# BL808 register map
File version: 0.1
Registers are access not given, no defined reset value unless marked. A register's access mark holds for its fields unless they carry their own. Offsets are from the block's base; [hi:lo] are bit positions; {n}, {i} and the like mark numbered series.

## DMA2D
Base 0x30006000
0x00 DMA2D_IntStatus
  [7:0] IntStatus ro — Status of the DMA interrupts after masking
0x04 DMA2D_IntTCStatus
  [7:0] IntTCStatus ro — Interrupt terminal count request status
0x08 DMA2D_IntTCClear
  [7:0] IntTCClear write-once — Terminal count request clear
0x0C DMA2D_EnbldChns
  [7:0] EnabledChannels ro — Channel enable status
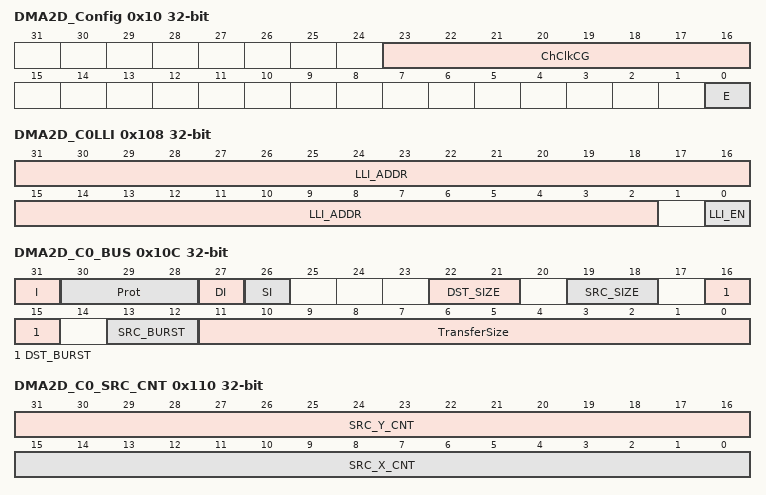
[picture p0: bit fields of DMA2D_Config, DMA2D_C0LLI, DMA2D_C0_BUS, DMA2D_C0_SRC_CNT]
0x10 DMA2D_Config
  [23:16] ChClkCG rw — Channel Clock cg enable
  [0] E rw — SMDMA Enable.
0x14 DMA2D_Sync rw
  [31:0] DMA_Sync — DMA synchronization logic for DMA request signals: 0 = enable, 1 = disable
0x18 DMA2D_SoftBReq rw
  [31:0] SoftBReq — Software burst request
0x1C DMA2D_SoftLBReq rw
  [31:0] SoftLBReq — Software last burst request
0x20 DMA2D_SoftSReq rw
  [31:0] SoftSReq — Software signle request
0x24 DMA2D_SoftLSReq rw
  [31:0] SoftLSReq — Software last signle request
0x100 DMA2D_C0SrcAddr rw
  [31:0] SrcAddr — DMA source address
0x104 DMA2D_C0DstAddr rw
  [31:0] DstAddr — DMA Destination address
0x108 DMA2D_C0LLI
  [31:2] LLI_ADDR rw — Next linked list address
  [0] LLI_EN rw — Next LLI enable
0x10C DMA2D_C0_BUS
  [31] I rw — Terminal count interrupt enable bit. It controls whether the current LLI is expected to trigger the terminal count interrupt.
  [30:28] Prot rw — Hprot Setting
  [27] DI rw — Only work when reg_dma_2d_en = 0 Destination increment. When set, the Destination address is incremented after each transfer.
  [26] SI rw — Only work when reg_dma_2d_en = 0 Source increment. When set, the source address is incremented after each transfer.
  [22:21] DST_SIZE rw — Destination transfer width: 8/16/32
  [19:18] SRC_SIZE rw — Source transfer width: 8/16/32
  [16:15] DST_BURST rw — Destination burst size: 1/4/8/16
  [13:12] SRC_BURST rw
  [11:0] TransferSize rw — Only work when reg_dma_2d_en = 0 Transfer size: 0~4095. Number of data transfers left to complete when the SMDMA is the flow controller.
0x110 DMA2D_C0_SRC_CNT rw
  [31:16] SRC_Y_CNT — Only work when reg_dma_2d_en = 1 Source Y-direction Count
  [15:0] SRC_X_CNT — Only work when reg_dma_2d_en = 1 Source X-direction Count
0x114 DMA2D_C0_SRC_XIC rw
  [31:0] SRC_X_INCR — Only work when reg_dma_2d_en = 1 Source Y-direction address increment Must allign "SWidth" setting [16] sign-bit
0x118 DMA2D_C0_SRC_YIC rw
  [31:0] SRC_Y_INCR — Only work when reg_dma_2d_en = 1 Source Y-direction address increment Must allign "SWidth" setting [16] sign-bit
0x11C DMA2D_C0_DST_CNT
  [15:0] DST_X_CNT rw — Only work when reg_dma_2d_en = 1 Source X-direction Count
0x120 DMA2D_C0_DST_XIC rw
  [31:0] DST_X_INCR — Only work when reg_dma_2d_en = 1 Source Y-direction address increment Must allign "SWidth" setting [16] sign-bit
0x124 DMA2D_C0_DST_YIC rw
  [31:0] DST_Y_INCR — Only work when reg_dma_2d_en = 1 Desitination Y-direction address increment Must allign "DWidth" setting [16] sign-bit
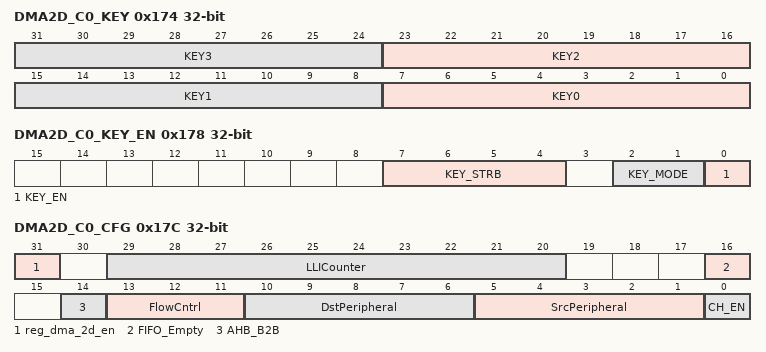
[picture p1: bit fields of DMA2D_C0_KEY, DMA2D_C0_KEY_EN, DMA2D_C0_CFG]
0x174 DMA2D_C0_KEY rw
  [8n+7:8n] KEY{n} (n=0..3) — Key value
0x178 DMA2D_C0_KEY_EN
  [7:4] KEY_STRB rw — According Key mode set Key STRB Key mode : Key STRB 2'd0 : 4'h1 2'd1 : 4'h3 2'd2 : 4'h7 2'd3 : 4'hf
  [2:1] KEY_MODE rw — Key Mode 2'd0 : 8-bit mode 2'd1 : 16-bit mode 2'd2 : 24-bit mode 2'd3 : 32-bit mode
  [0] KEY_EN rw — Key enable
0x17C DMA2D_C0_CFG
  [31] reg_dma_2d_en rw — DMA 2d enable
  [29:20] LLICounter ro — LLI counter. Increased 1 each LLI run. Cleared 0 when config Control.
  [16] FIFO_Empty ro — Active: 0 = no data in FIFO of the channel, 1 = FIFO of the channel has data.
  [14] AHB_B2B rw — AHB back to back enable
  [13:11] FlowCntrl rw — 000: Memory-to-memory (DMA) 001: Memory-to-peripheral (DMA) 010: Peripheral-to-memory (DMA) 011: Source peripheral-to-Destination peripheral (DMA) The following only work when reg_dma_2d_en=0 : 100: Source peripheral-to-Destination peripheral (Destination peripheral) 101: Memory-to-peripheral (peripheral) 110: Peripheral-to-memory (peripheral) 111: Source peripheral-to-Destination peripheral (Source peripheral)
  [10:6] DstPeripheral rw — Destination peripheral.
  [5:1] SrcPeripheral rw — Source peripheral.
  [0] CH_EN rw — Channel enable.
